# LPC11Uxx register map
File version: 7
CPU: CM0 r0p0, little endian, no MPU, no FPU, 2 interrupt priority bits
Registers are 32-bit, read-write, reset 0x0 unless marked. A register's access mark holds for its fields unless they carry their own. Offsets are from the block's base; [hi:lo] are bit positions; {n}, {i} and the like mark numbered series; 'fields as' and 'values as' point back to an identical list.

## USB — USB2.0 device controller
Base 0x40080000
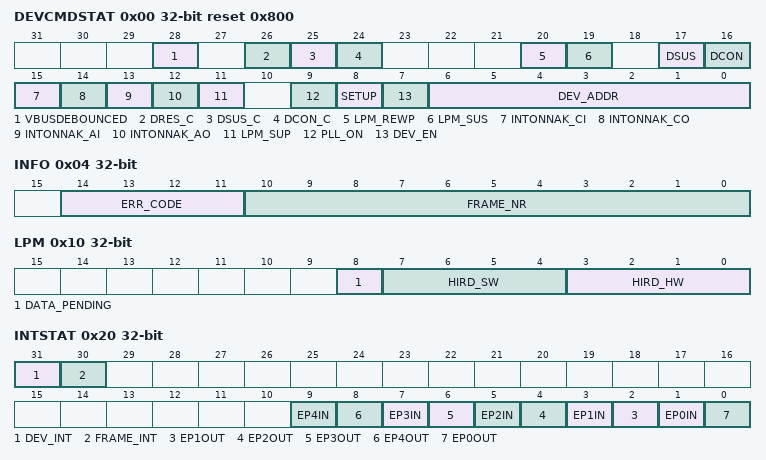
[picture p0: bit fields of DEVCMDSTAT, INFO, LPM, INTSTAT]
0x00 DEVCMDSTAT reset 0x800 — USB Device Command/Status register
  [28] VBUSDEBOUNCED — This bit indicates if Vbus is detected or not. The bit raises immediately when Vbus becomes high. It drops to zero if Vbus is low for at least 3 ms. If this bit is high and the DCon bit is set, the HW will enable the pull-up resistor to signal a connect.
  [26] DRES_C — Device status - reset change. This bit is set when the device received a bus reset. On a bus reset the device will automatically go to the default state (unconfigured and responding to address 0). The bit is reset by writing a one to it.
  [25] DSUS_C — Device status - suspend change. The suspend change bit is set to 1 when the suspend bit toggles. The suspend bit can toggle because: - The device goes in the suspended state - The device is disconnected - The device receives resume signaling on its upstream port. The bit is reset by writing a one to it.
  [24] DCON_C — Device status - connect change. The Connect Change bit is set when the device's pull-up resistor is disconnected because VBus disappeared. The bit is reset by writing a one to it.
  [20] LPM_REWP — LPM Remote Wake-up Enabled by USB host. HW sets this bit to one when the bRemoteWake bit in the LPM extended token is set to 1. HW will reset this bit to 0 when it receives the host initiated LPM resume, when a remote wake-up is sent by the device or when a USB bus reset is received. Software can use this bit to check if the remote wake-up feature is enabled by the host for the LPM transaction.
  [19] LPM_SUS — Device status - LPM Suspend. This bit represents the current LPM suspend state. It is set to 1 by HW when the device has acknowledged the LPM request from the USB host and the Token Retry Time of 10us has elapsed. When the device is in the LPM suspended state (LPM suspend bit = 1) and the software writes a zero to this bit, the device will generate a remote walk-up. Software can only write a zero to this bit when the LPM_REWP bit is set to 1. HW resets this bit when it receives a host initiated resume. HW only updates the LPM_SUS bit when the LPM_SUPP bit is equal to one.
  [17] DSUS — Device status - suspend. The suspend bit indicates the current suspend state. It is set to 1 when the device hasn't seen any activity on its upstream port for more than 3 milliseconds. It is reset to 0 on any activity. When the device is suspended (Suspend bit DSUS = 1) and the software writes a 0 to it, the device will generate a remote wake-up. This will only happen when the device is connected (Connect bit = 1). When the device is not connected or not suspended, a writing a 0 has no effect. Writing a 1 never has an effect.
  [16] DCON — Device status - connect. The connect bit must be set by SW to indicate that the device must signal a connect. The pull-up resistor on USB_DP will be enabled when this bit is set and the VbusDebounced bit is one.
  [15] INTONNAK_CI — Interrupt on NAK for control IN EP
    0=ACKNOW (Only acknowledged packets generate an interrupt); 1=ACKNOW_NAK (Both acknowledged and NAKed packets generate interrupts.)
  [14] INTONNAK_CO — Interrupt on NAK for control OUT EP
    values as INTONNAK_CI
  [13] INTONNAK_AI — Interrupt on NAK for interrupt and bulk IN EP
    values as INTONNAK_CI
  [12] INTONNAK_AO — Interrupt on NAK for interrupt and bulk OUT EP
    values as INTONNAK_CI
  [11] LPM_SUP — LPM Supported:
    0=NOT_SUPPORTED (LPM not supported.); 1=SUPPORTED (LPM supported.)
  [9] PLL_ON — Always PLL Clock on:
    0=USB_NEEDCLK_FUNCTION (USB_NeedClk functional); 1=USB_NEEDCLK_ALWAYS_1 (USB_NeedClk always 1. Clock will not be stopped in case of suspend.)
  [8] SETUP — SETUP token received. If a SETUP token is received and acknowledged by the device, this bit is set. As long as this bit is set all received IN and OUT tokens will be NAKed by HW. SW must clear this bit by writing a one. If this bit is zero, HW will handle the tokens to the CTRL EP0 as indicated by the CTRL EP0 IN and OUT data information programmed by SW.
  [7] DEV_EN — USB device enable. If this bit is set, the HW will start responding on packets for function address DEV_ADDR.
  [6:0] DEV_ADDR — USB device address. After bus reset, the address is reset to 0x00. If the enable bit is set, the device will respond on packets for function address DEV_ADDR. When receiving a SetAddress Control Request from the USB host, software must program the new address before completing the status phase of the SetAddress Control Request.
0x04 INFO — USB Info register
  [14:11] ERR_CODE — The error code which last occurred:
    0=NO_ERROR; 1=PID_ENCODING_ERROR; 2=PID_UNKNOWN; 3=PACKET_UNEXPECTED; 4=TOKEN_CRC_ERROR; 5=DATA_CRC_ERROR; 6=TIME_OUT; 7=BABBLE; 8=TRUNCATED_EOP; 9=SENTRECEIVED_NAK; 10=SENT_STALL; 11=OVERRUN; 12=SENT_EMPTY_PACKET; 13=BITSTUFF_ERROR; 14=SYNC_ERROR; 15=WRONG_DATA_TOGGLE
  [10:0] FRAME_NR — Frame number. This contains the frame number of the last successfully received SOF. In case no SOF was received by the device at the beginning of a frame, the frame number returned is that of the last successfully received SOF. In case the SOF frame number contained a CRC error, the frame number returned will be the corrupted frame number as received by the device.
0x08 EPLISTSTART — USB EP Command/Status List start address
  [31:8] EP_LIST — Start address of the USB EP Command/Status List.
0x0C DATABUFSTART — USB Data buffer start address
  [31:22] DA_BUF — Start address of the buffer pointer page where all endpoint data buffers are located.
0x10 LPM — Link Power Management register
  [8] DATA_PENDING — As long as this bit is set to one and LPM supported bit is set to one, HW will return a NYET handshake on every LPM token it receives. If LPM supported bit is set to one and this bit is zero, HW will return an ACK handshake on every LPM token it receives. If SW has still data pending and LPM is supported, it must set this bit to 1.
  [7:4] HIRD_SW — Host Initiated Resume Duration - SW. This is the time duration required by the USB device system to come out of LPM initiated suspend after receiving the host initiated LPM resume.
  [3:0] HIRD_HW — Host Initiated Resume Duration - HW. This is the HIRD value from the last received LPM token
0x14 EPSKIP — USB Endpoint skip
  [29:0] SKIP — Endpoint skip: Writing 1 to one of these bits, will indicate to HW that it must deactivate the buffer assigned to this endpoint and return control back to software. When HW has deactivated the endpoint, it will clear this bit, but it will not modify the EPINUSE bit. An interrupt will be generated when the Active bit goes from 1 to 0. Note: In case of double-buffering, HW will only clear the Active bit of the buffer indicated by the EPINUSE bit.
0x18 EPINUSE — USB Endpoint Buffer in use
  [9:2] BUF — Buffer in use: This register has one bit per physical endpoint. 0: HW is accessing buffer 0. 1: HW is accessing buffer 1.
0x1C EPBUFCFG — USB Endpoint Buffer Configuration register
  [9:2] BUF_SB — Buffer usage: This register has one bit per physical endpoint. 0: Single-buffer. 1: Double-buffer. If the bit is set to single-buffer (0), it will not toggle the corresponding EPINUSE bit when it clears the active bit. If the bit is set to double-buffer (1), HW will toggle the EPINUSE bit when it clears the Active bit for the buffer.
0x20 INTSTAT — USB interrupt status register
  [31] DEV_INT — Device status interrupt. This bit is set by HW when one of the bits in the Device Status Change register are set. Software can clear this bit by writing a one to it.
  [30] FRAME_INT — Frame interrupt. This bit is set to one every millisecond when the VbusDebounced bit and the DCON bit are set. This bit can be used by software when handling isochronous endpoints. Software can clear this bit by writing a one to it.
  [2n+1] EP{n}IN (n=1..4) — Interrupt status register bit for the EP{n} IN direction. This bit will be set if the corresponding Active bit is cleared by HW. This is done in case the programmed NBytes transitions to zero or the skip bit is set by software. If the IntOnNAK_AI is set, this bit will also be set when a NAK is transmitted for the EP{n} IN direction. Software can clear this bit by writing a one to it.
  [2n] EP{n}OUT (n=1..4) — Interrupt status register bit for the EP{n} OUT direction. This bit will be set if the corresponding Active bit is cleared by HW. This is done in case the programmed NBytes transitions to zero or the skip bit is set by software. If the IntOnNAK_AO is set, this bit will also be set when a NAK is transmitted for the EP{n} OUT direction. Software can clear this bit by writing a one to it.
  [1] EP0IN — Interrupt status register bit for the Control EP0 IN direction. This bit will be set if NBytes transitions to zero or the skip bit is set by software. If the IntOnNAK_CI is set, this bit will also be set when a NAK is transmitted for the Control EP0 IN direction. Software can clear this bit by writing a one to it.
  [0] EP0OUT — Interrupt status register bit for the Control EP0 OUT direction. This bit will be set if NBytes transitions to zero or the skip bit is set by software or a SETUP packet is successfully received for the control EP0. If the IntOnNAK_CO is set, this bit will also be set when a NAK is transmitted for the Control EP0 OUT direction. Software can clear this bit by writing a one to it.
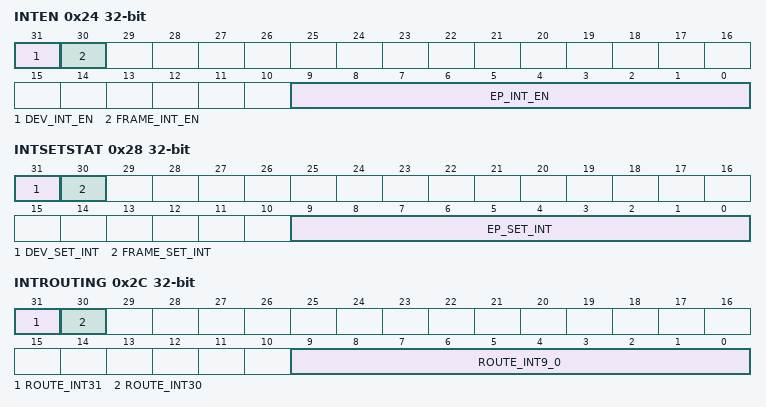
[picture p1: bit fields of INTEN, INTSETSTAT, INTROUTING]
0x24 INTEN — USB interrupt enable register
  [31] DEV_INT_EN — If this bit is set and the corresponding USB interrupt status bit is set, a HW interrupt is generated on the interrupt line indicated by the corresponding USB interrupt routing bit.
  [30] FRAME_INT_EN — If this bit is set and the corresponding USB interrupt status bit is set, a HW interrupt is generated on the interrupt line indicated by the corresponding USB interrupt routing bit.
  [9:0] EP_INT_EN — If this bit is set and the corresponding USB interrupt status bit is set, a HW interrupt is generated on the interrupt line indicated by the corresponding USB interrupt routing bit.
0x28 INTSETSTAT — USB set interrupt status register
  [31] DEV_SET_INT — If software writes a one to one of these bits, the corresponding USB interrupt status bit is set. When this register is read, the same value as the USB interrupt status register is returned.
  [30] FRAME_SET_INT — If software writes a one to one of these bits, the corresponding USB interrupt status bit is set. When this register is read, the same value as the USB interrupt status register is returned.
  [9:0] EP_SET_INT — If software writes a one to one of these bits, the corresponding USB interrupt status bit is set. When this register is read, the same value as the USB interrupt status register is returned.
0x2C INTROUTING — USB interrupt routing register
  [31] ROUTE_INT31 — This bit can control on which hardware interrupt line the interrupt will be generated: 0: IRQ interrupt line is selected for this interrupt bit 1: FIQ interrupt line is selected for this interrupt bit
  [30] ROUTE_INT30 — This bit can control on which hardware interrupt line the interrupt will be generated: 0: IRQ interrupt line is selected for this interrupt bit 1: FIQ interrupt line is selected for this interrupt bit
  [9:0] ROUTE_INT9_0 — This bit can control on which hardware interrupt line the interrupt will be generated: 0: IRQ interrupt line is selected for this interrupt bit 1: FIQ interrupt line is selected for this interrupt bit
0x34 EPTOGGLE ro — USB Endpoint toggle register
  [9:0] TOGGLE — Endpoint data toggle: This field indicates the current value of the data toggle for the corresponding endpoint.
